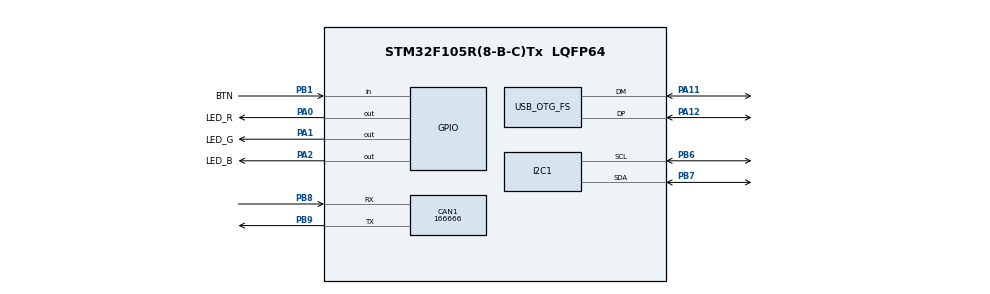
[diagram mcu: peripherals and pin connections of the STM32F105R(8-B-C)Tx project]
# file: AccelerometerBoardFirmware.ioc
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CAN1.CalculateBaudRate=166666
CAN1.CalculateTimeBit=6000
CAN1.CalculateTimeQuantum=2000.0
Mcu.Family=STM32F1
Mcu.Name=STM32F105R(8-B-C)Tx
Mcu.Package=LQFP64
NVIC.PriorityGroup=NVIC_PRIORITYGROUP_4
PA0-WKUP.GPIO_Label=LED_R
PA0-WKUP.Signal=GPIO_Output
PA1.GPIO_Label=LED_G
PA1.Signal=GPIO_Output
PA11.Mode=Device_Only
PA11.Signal=USB_OTG_FS_DM
PA12.Mode=Device_Only
PA12.Signal=USB_OTG_FS_DP
PA13.Mode=Serial_Wire
PA13.Signal=SYS_JTMS-SWDIO
PA14.Mode=Serial_Wire
PA14.Signal=SYS_JTCK-SWCLK
PA2.GPIO_Label=LED_B
PA2.Signal=GPIO_Output
PB1.GPIO_Label=BTN
PB1.Signal=GPIO_Input
PB6.Mode=I2C
PB6.Signal=I2C1_SCL
PB7.Mode=I2C
PB7.Signal=I2C1_SDA
PB8.Mode=CAN_Activate
PB8.Signal=CAN1_RX
PB9.Mode=CAN_Activate
PB9.Signal=CAN1_TX
PD0-OSC_IN.Mode=HSE-External-Oscillator
PD0-OSC_IN.Signal=RCC_OSC_IN
PD1-OSC_OUT.Mode=HSE-External-Oscillator
PD1-OSC_OUT.Signal=RCC_OSC_OUT
ProjectManager.HeapSize=0x200
ProjectManager.StackSize=0x400
ProjectManager.TargetToolchain=STM32CubeIDE
RCC.PLLSource=RCC_PLLSOURCE_HSI_DIV2
RCC.PLLSourceVirtual=RCC_PLLSOURCE_HSI_DIV2
RCC.USBFreq_Value=10666666.666666666
USB_OTG_FS.VirtualMode=Device_Only
board=custom

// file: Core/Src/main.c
/* USER CODE BEGIN Header */
/**
  ******************************************************************************
  * @file           : main.c
  * @brief          : Main program body
  ******************************************************************************
  * @attention
  *
  * Copyright (c) 2022 STMicroelectronics.
  * All rights reserved.
  *
  * This software is licensed under terms that can be found in the LICENSE file
  * in the root directory of this software component.
  * If no LICENSE file comes with this software, it is provided AS-IS.
  *
  ******************************************************************************
  */
/* USER CODE END Header */
#include "main.h"

/* USER CODE BEGIN Includes */
#include "project.h"
/* USER CODE END Includes */

CAN_HandleTypeDef hcan1;

I2C_HandleTypeDef hi2c1;

PCD_HandleTypeDef hpcd_USB_OTG_FS;

void SystemClock_Config(void);
static void MX_GPIO_Init(void);
static void MX_CAN1_Init(void);
static void MX_I2C1_Init(void);
static void MX_USB_OTG_FS_PCD_Init(void);

int main(void)
{

  /* MCU Configuration--------------------------------------------------------*/

  /* Reset of all peripherals, Initializes the Flash interface and the Systick. */
  HAL_Init();

  /* Configure the system clock */
  SystemClock_Config();

  /* Initialize all configured peripherals */
  MX_GPIO_Init();
  MX_CAN1_Init();
  MX_I2C1_Init();
  MX_USB_OTG_FS_PCD_Init();
  /* USER CODE BEGIN 2 */
  projectMain();
  /* USER CODE END 2 */

  /* Infinite loop */
  while (1)
  {

  }
}

void SystemClock_Config(void)
{
  RCC_OscInitTypeDef RCC_OscInitStruct = {0};
  RCC_ClkInitTypeDef RCC_ClkInitStruct = {0};
  RCC_PeriphCLKInitTypeDef PeriphClkInit = {0};

  /** Initializes the RCC Oscillators according to the specified parameters
  * in the RCC_OscInitTypeDef structure.
  */
  RCC_OscInitStruct.OscillatorType = RCC_OSCILLATORTYPE_HSI;
  RCC_OscInitStruct.HSIState = RCC_HSI_ON;
  RCC_OscInitStruct.HSICalibrationValue = RCC_HSICALIBRATION_DEFAULT;
  RCC_OscInitStruct.Prediv1Source = RCC_PREDIV1_SOURCE_HSE;
  RCC_OscInitStruct.PLL.PLLState = RCC_PLL_ON;
  RCC_OscInitStruct.PLL.PLLSource = RCC_PLLSOURCE_HSI_DIV2;
  RCC_OscInitStruct.PLL.PLLMUL = RCC_PLL_MUL4;
  RCC_OscInitStruct.PLL2.PLL2State = RCC_PLL_NONE;
  if (HAL_RCC_OscConfig(&RCC_OscInitStruct) != HAL_OK)
  {
    Error_Handler();
  }

  /** Initializes the CPU, AHB and APB buses clocks
  */
  RCC_ClkInitStruct.ClockType = RCC_CLOCKTYPE_HCLK|RCC_CLOCKTYPE_SYSCLK
                              |RCC_CLOCKTYPE_PCLK1|RCC_CLOCKTYPE_PCLK2;
  RCC_ClkInitStruct.SYSCLKSource = RCC_SYSCLKSOURCE_HSI;
  RCC_ClkInitStruct.AHBCLKDivider = RCC_SYSCLK_DIV1;
  RCC_ClkInitStruct.APB1CLKDivider = RCC_HCLK_DIV1;
  RCC_ClkInitStruct.APB2CLKDivider = RCC_HCLK_DIV1;

  if (HAL_RCC_ClockConfig(&RCC_ClkInitStruct, FLASH_LATENCY_0) != HAL_OK)
  {
    Error_Handler();
  }
  PeriphClkInit.PeriphClockSelection = RCC_PERIPHCLK_USB;
  PeriphClkInit.UsbClockSelection = RCC_USBCLKSOURCE_PLL_DIV3;
  if (HAL_RCCEx_PeriphCLKConfig(&PeriphClkInit) != HAL_OK)
  {
    Error_Handler();
  }

  /** Configure the Systick interrupt time
  */
  __HAL_RCC_PLLI2S_ENABLE();
}

static void MX_CAN1_Init(void)
{

  hcan1.Instance = CAN1;
  hcan1.Init.Prescaler = 16;
  hcan1.Init.Mode = CAN_MODE_NORMAL;
  hcan1.Init.SyncJumpWidth = CAN_SJW_1TQ;
  hcan1.Init.TimeSeg1 = CAN_BS1_1TQ;
  hcan1.Init.TimeSeg2 = CAN_BS2_1TQ;
  hcan1.Init.TimeTriggeredMode = DISABLE;
  hcan1.Init.AutoBusOff = DISABLE;
  hcan1.Init.AutoWakeUp = DISABLE;
  hcan1.Init.AutoRetransmission = DISABLE;
  hcan1.Init.ReceiveFifoLocked = DISABLE;
  hcan1.Init.TransmitFifoPriority = DISABLE;
  if (HAL_CAN_Init(&hcan1) != HAL_OK)
  {
    Error_Handler();
  }

}

static void MX_I2C1_Init(void)
{

  hi2c1.Instance = I2C1;
  hi2c1.Init.ClockSpeed = 100000;
  hi2c1.Init.DutyCycle = I2C_DUTYCYCLE_2;
  hi2c1.Init.OwnAddress1 = 0;
  hi2c1.Init.AddressingMode = I2C_ADDRESSINGMODE_7BIT;
  hi2c1.Init.DualAddressMode = I2C_DUALADDRESS_DISABLE;
  hi2c1.Init.OwnAddress2 = 0;
  hi2c1.Init.GeneralCallMode = I2C_GENERALCALL_DISABLE;
  hi2c1.Init.NoStretchMode = I2C_NOSTRETCH_DISABLE;
  if (HAL_I2C_Init(&hi2c1) != HAL_OK)
  {
    Error_Handler();
  }

}

static void MX_USB_OTG_FS_PCD_Init(void)
{

  hpcd_USB_OTG_FS.Instance = USB_OTG_FS;
  hpcd_USB_OTG_FS.Init.dev_endpoints = 4;
  hpcd_USB_OTG_FS.Init.speed = PCD_SPEED_FULL;
  hpcd_USB_OTG_FS.Init.phy_itface = PCD_PHY_EMBEDDED;
  hpcd_USB_OTG_FS.Init.Sof_enable = DISABLE;
  hpcd_USB_OTG_FS.Init.low_power_enable = DISABLE;
  hpcd_USB_OTG_FS.Init.vbus_sensing_enable = DISABLE;
  if (HAL_PCD_Init(&hpcd_USB_OTG_FS) != HAL_OK)
  {
    Error_Handler();
  }

}

static void MX_GPIO_Init(void)
{
  GPIO_InitTypeDef GPIO_InitStruct = {0};

  /* GPIO Ports Clock Enable */
  __HAL_RCC_GPIOD_CLK_ENABLE();
  __HAL_RCC_GPIOA_CLK_ENABLE();
  __HAL_RCC_GPIOB_CLK_ENABLE();

  /*Configure GPIO pin Output Level */
  HAL_GPIO_WritePin(GPIOA, LED_R_Pin|LED_G_Pin|LED_B_Pin, GPIO_PIN_RESET);

  /*Configure GPIO pins : LED_R_Pin LED_G_Pin LED_B_Pin */
  GPIO_InitStruct.Pin = LED_R_Pin|LED_G_Pin|LED_B_Pin;
  GPIO_InitStruct.Mode = GPIO_MODE_OUTPUT_PP;
  GPIO_InitStruct.Pull = GPIO_NOPULL;
  GPIO_InitStruct.Speed = GPIO_SPEED_FREQ_LOW;
  HAL_GPIO_Init(GPIOA, &GPIO_InitStruct);

  /*Configure GPIO pin : BTN_Pin */
  GPIO_InitStruct.Pin = BTN_Pin;
  GPIO_InitStruct.Mode = GPIO_MODE_INPUT;
  GPIO_InitStruct.Pull = GPIO_NOPULL;
  HAL_GPIO_Init(BTN_GPIO_Port, &GPIO_InitStruct);

}

void Error_Handler(void)
{
  __disable_irq();
  while (1)
  {
  }
}
